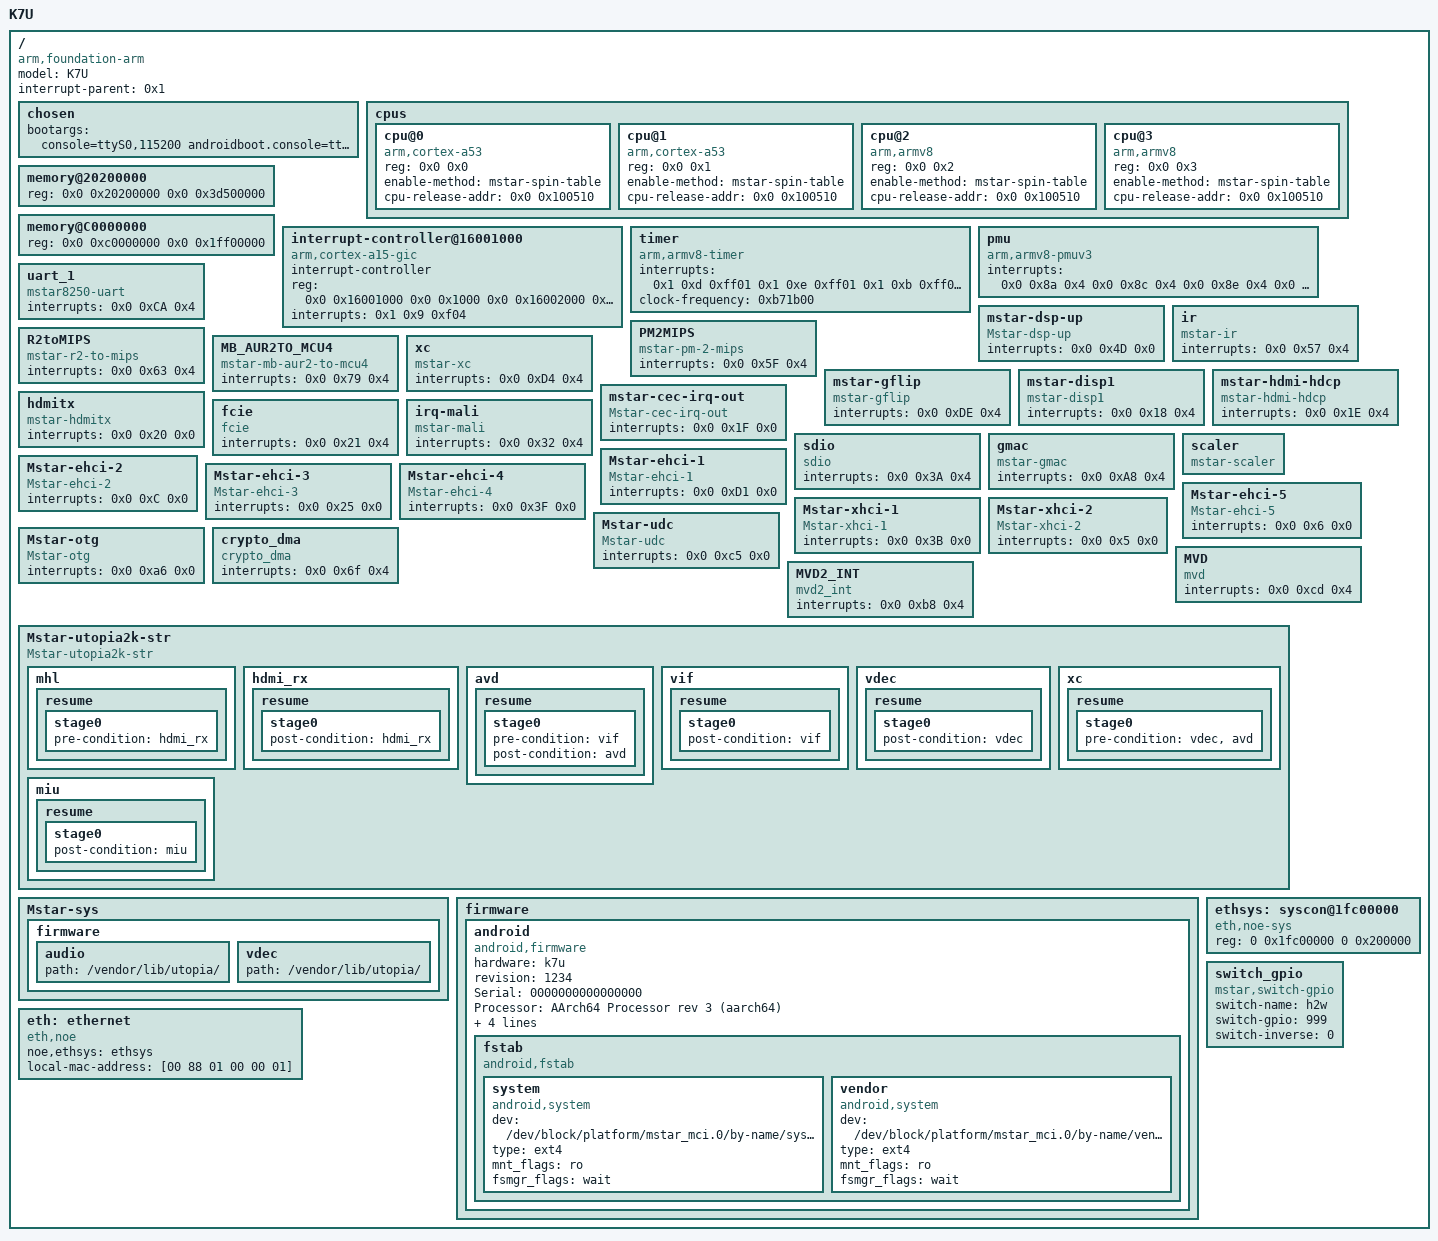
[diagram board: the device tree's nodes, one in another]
/dts-v1/;

/ {
	model = "K7U";
	compatible = "arm,foundation-arm", "arm,k7u";
	interrupt-parent = <0x1>;
	#address-cells = <0x2>;
	#size-cells = <0x2>;

	chosen {
		bootargs = "console=ttyS0,115200 androidboot.console=ttyS0 root=/dev/ram rw rootwait init=/init CORE_DUMP_PATH=/data/core_dump.%%p.gz KDebug=1 delaylogo=true androidboot.selinux=permissive LX_MEM=0x3D500000 LX_MEM2=0xC0000000,0x1FF00000 EMAC_MEM=0x100000 PM51_ADDR=0x20010000 PM51_LEN=0x10000 CMA0=OTHERS,miu=0,hid=23,sz=0x7000000,st=0x11000000 CMA1=VDEC0,miu=0,hid=20,sz=0x3000000,st=0x18000000 CMA2=XC0,miu=0,hid=22,sz=0x6000000,st=0x1b000000 CMA3=OTHERS2,miu=1,hid=24,sz=0xec00000,st=0x0 CMA4=VDEC1,miu=1,hid=19,sz=0x7000000,st=0xec00000 CMA5=RETURN_ENUM,miu=1,hid=25,sz=0x2400000,st=0x15c00000 BOOTLOGO_IN_MBOOT ENV_VAR_OFFSET=0x0 ENV_VAR_SIZE=0x10000 ENV=EMMC SECURITY=ON";
	};

	cpus {
		#address-cells = <0x2>;
		#size-cells = <0x0>;

		cpu@0 {
			compatible = "arm,cortex-a53", "arm,armv8";
			reg = <0x0 0x0>;
			device_type = "cpu";
			enable-method = "mstar-spin-table";
			cpu-release-addr = <0x0 0x100510>;
			linux,phandle = <0x2>;
			phandle = <0x2>;
		};

		cpu@1 {
			compatible = "arm,cortex-a53", "arm,armv8";
			reg = <0x0 0x1>;
			device_type = "cpu";
			enable-method = "mstar-spin-table";
			cpu-release-addr = <0x0 0x100510>;
			linux,phandle = <0x3>;
			phandle = <0x3>;
		};

		cpu@2 {
			device_type = "cpu";
			compatible = "arm,armv8";
			reg = <0x0 0x2>;
			enable-method = "mstar-spin-table";
			cpu-release-addr = <0x0 0x100510>;
		};

		cpu@3 {
			device_type = "cpu";
			compatible = "arm,armv8";
			reg = <0x0 0x3>;
			enable-method = "mstar-spin-table";
			cpu-release-addr = <0x0 0x100510>;
		};
	};

	memory@20200000 {
		device_type = "memory";
		reg = <0x0 0x20200000 0x0 0x3d500000>;
	};

	memory@C0000000 {
		device_type = "memory";
		reg = <0x0 0xc0000000 0x0 0x1ff00000>;
	};

	interrupt-controller@16001000 {
		compatible = "arm,cortex-a15-gic", "arm,cortex-a9-gic";
		#interrupt-cells = <0x3>;
		#address-cells = <0x0>;
		interrupt-controller;
		reg = <0x0 0x16001000 0x0 0x1000 0x0 0x16002000 0x0 0x4000>;
		interrupts = <0x1 0x9 0xf04>;
		linux,phandle = <0x1>;
		phandle = <0x1>;
	};

	timer {
		compatible = "arm,armv8-timer";
		interrupts = <0x1 0xd 0xff01 0x1 0xe 0xff01 0x1 0xb 0xff01 0x1 0xa 0xff01>;
		clock-frequency = <0xb71b00>;
	};

	pmu {
		compatible = "arm,armv8-pmuv3";
		interrupts = <0x0 0x8a 0x4 0x0 0x8c 0x4 0x0 0x8e 0x4 0x0 0x8f 0x4>;
	};

	uart_1 {
		compatible = "mstar8250-uart";
		interrupts = <0x0 0xCA 0x4>;
	};

	mstar-dsp-up {
		compatible = "Mstar-dsp-up";
		interrupts = <0x0 0x4D 0x0>;
	};

	ir {
		compatible = "mstar-ir";
		interrupts = <0x0 0x57 0x4>;
	};

	PM2MIPS {
		compatible = "mstar-pm-2-mips";
		interrupts = <0x0 0x5F 0x4>;
	};

	R2toMIPS {
		compatible = "mstar-r2-to-mips";
		interrupts = <0x0 0x63 0x4>;
	};

	MB_AUR2TO_MCU4 {
		compatible = "mstar-mb-aur2-to-mcu4";
		interrupts = <0x0 0x79 0x4>;
	};

	xc {
		compatible = "mstar-xc";
		interrupts = <0x0 0xD4 0x4>;
	};

	mstar-gflip {
		compatible = "mstar-gflip";
		interrupts = <0x0 0xDE 0x4>;
	};

	mstar-disp1 {
		compatible = "mstar-disp1";
		interrupts = <0x0 0x18 0x4>;
	};

	mstar-hdmi-hdcp {
		compatible = "mstar-hdmi-hdcp";
		interrupts = <0x0 0x1E 0x4>;
	};

	mstar-cec-irq-out {
		compatible = "Mstar-cec-irq-out";
		interrupts = <0x0 0x1F 0x0>;
	};

	hdmitx {
		compatible = "mstar-hdmitx";
		interrupts = <0x0 0x20 0x0>;
	};

	fcie {
		compatible = "fcie";
		interrupts = <0x0 0x21 0x4>;
	};

	irq-mali {
		compatible = "mstar-mali";
		interrupts = <0x0 0x32 0x4>;
	};

	sdio {
		compatible = "sdio";
		interrupts = <0x0 0x3A 0x4>;
	};

	gmac {
		compatible = "mstar-gmac";
		interrupts = <0x0 0xA8 0x4>;
	};

	scaler {
		compatible = "mstar-scaler";
	};

	Mstar-ehci-1 {
		compatible = "Mstar-ehci-1";
		interrupts = <0x0 0xD1 0x0>;
	};

	Mstar-ehci-2 {
		compatible = "Mstar-ehci-2";
		interrupts = <0x0 0xC 0x0>;
	};

	Mstar-ehci-3 {
		compatible = "Mstar-ehci-3";
		interrupts = <0x0 0x25 0x0>;
	};

	Mstar-ehci-4 {
		compatible = "Mstar-ehci-4";
		interrupts = <0x0 0x3F 0x0>;
	};

	Mstar-ehci-5 {
		compatible = "Mstar-ehci-5";
		interrupts = <0x0 0x6 0x0>;
	};

	Mstar-xhci-1 {
		compatible = "Mstar-xhci-1";
		interrupts = <0x0 0x3B 0x0>;
	};

    Mstar-xhci-2 {
		compatible = "Mstar-xhci-2";
		interrupts = <0x0 0x5 0x0>;
	};

	Mstar-udc {
		compatible = "Mstar-udc";
		interrupts = <0x0 0xc5 0x0>;
	};

	Mstar-otg {
		compatible = "Mstar-otg";
		interrupts = <0x0 0xa6 0x0>;
	};

	crypto_dma {
		compatible = "crypto_dma";
		interrupts = <0x0 0x6f 0x4>;
	};

	MVD {
        compatible = "mvd";
        interrupts = <0x0 0xcd 0x4>;
	};

	MVD2_INT {
        compatible = "mvd2_int";
        interrupts = <0x0 0xb8 0x4>;
	};

	Mstar-utopia2k-str {
		compatible = "Mstar-utopia2k-str";
		mhl {
		  resume {
		    stage0 {
		      pre-condition = "hdmi_rx";
		    };
		  };
		};
		hdmi_rx {
		  resume {
		    stage0 {
		      post-condition = "hdmi_rx";
		    };
		  };
		};
		avd {
		  resume {
		    stage0 {
		      pre-condition = "vif";
		      post-condition = "avd";
		    };
		  };
		};
		vif {
		  resume {
		    stage0 {
		      post-condition = "vif";
		    };
		  };
		};
		vdec {
		  resume {
		    stage0 {
		      post-condition = "vdec";
		    };
		  };
		};
		xc {
		  resume {
		    stage0 {
		      pre-condition = "vdec","avd";
		    };
		  };
		};
        miu {
          resume {
            stage0 {
              post-condition = "miu";
            };
          };
        };
	};

	Mstar-sys {
		firmware {
			audio {
				path = "/vendor/lib/utopia/";
			};
			vdec {
				path = "/vendor/lib/utopia/";
			};
		};
	};

	firmware {
		android {
			compatible = "android,firmware";
			hardware ="k7u";
			revision ="1234";
			Serial   ="0000000000000000";
			Processor ="AArch64 Processor rev 3 (aarch64)";
			serialno ="123456789";
			mode ="123456789";
			baseband ="123456789";
			bootloader ="123456789";
			fstab {
				compatible = "android,fstab";
				system {
					compatible = "android,system";
					dev = "/dev/block/platform/mstar_mci.0/by-name/system";
					type = "ext4";
					mnt_flags = "ro";
					fsmgr_flags = "wait";
				};
				vendor {
					compatible = "android,system";
					dev = "/dev/block/platform/mstar_mci.0/by-name/vendor";
					type = "ext4";
					mnt_flags = "ro";
					fsmgr_flags = "wait";
				};
			};
		};
	};

    ethsys: syscon@1fc00000 {
        #address-cells = <1>;
        #size-cells = <1>;
        compatible = "eth,noe-sys", "syscon";
        reg = <0 0x1fc00000 0 0x200000>;
        #clock-cells = <1>;
    };

	switch_gpio {
		compatible = "mstar,switch-gpio";
		switch-name = "h2w";
		switch-gpio = <999>;
		switch-inverse = <0>;
	};

    eth: ethernet{
        compatible = "eth,noe";
        noe,ethsys = <&ethsys>;
        #reset-cells = <1>;
        #address-cells = <1>;
        #size-cells = <0>;
        local-mac-address = [00 88 01 00 00 01];
        status = "okay";
    };
};
